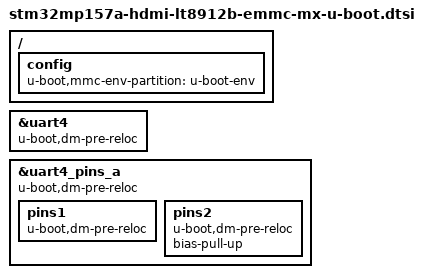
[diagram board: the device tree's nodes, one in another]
// SPDX-License-Identifier: (GPL-2.0+ OR MIT)
/*
 * Copyright 2024 SoMLabs
 */

#include "stm32mp15-scmi-u-boot.dtsi"

/ {
	config {
		u-boot,mmc-env-partition = "u-boot-env";
	};

};

&uart4 {
        u-boot,dm-pre-reloc;
};

&uart4_pins_a {
        u-boot,dm-pre-reloc;
        pins1 {
                u-boot,dm-pre-reloc;
        };
        pins2 {
                u-boot,dm-pre-reloc;
                bias-pull-up;
        };
};

